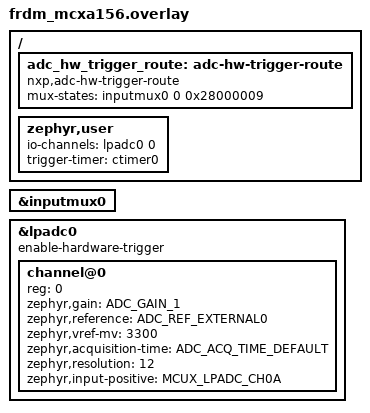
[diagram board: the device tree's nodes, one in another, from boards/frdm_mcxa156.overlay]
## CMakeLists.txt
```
# SPDX-FileCopyrightText: Copyright 2026 NXP
# SPDX-License-Identifier: Apache-2.0

cmake_minimum_required(VERSION 3.20.0)

# Make the sample-local DTS binding visible to the Zephyr DTS toolchain.
# DTS_ROOT must be set before find_package(Zephyr).
list(APPEND DTS_ROOT ${CMAKE_CURRENT_SOURCE_DIR})

find_package(Zephyr REQUIRED HINTS $ENV{ZEPHYR_BASE})
project(trgmux_adc)

target_sources(app PRIVATE src/main.c)
```

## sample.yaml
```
sample:
  name: ADC Hardware Trigger via Signal Router
  description: >
    Demonstrates routing a periodic timer output to an ADC trigger input via a
    signal-routing peripheral (TRGMUX, INPUTMUX, XBAR, …). The C source is
    platform-agnostic; all per-board wiring lives in the board overlay.

tests:
  sample.drivers.mux.trgmux_adc:
    platform_allow:
      - frdm_mcxe247
      - frdm_mcxa156
    tags:
      - adc
      - mux
      - counter
      - drivers
    harness: console
    harness_config:
      type: one_line
      regex:
        - "ADC reading"
```

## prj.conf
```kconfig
CONFIG_ADC=y
CONFIG_COUNTER=y
CONFIG_MUX=y
CONFIG_LOG=y
```

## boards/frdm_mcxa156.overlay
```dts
/*
 * SPDX-FileCopyrightText: Copyright 2026 NXP
 * SPDX-License-Identifier: Apache-2.0
 *
 * frdm_mcxa156: Route CTimer0 match-0 output to LPADC0 trigger0 via INPUTMUX.
 *
 * CTimer0 and LPADC0 are already enabled in frdm_mcxa156.dts; INPUTMUX is
 * disabled by default in the SoC dtsi and is enabled here.
 *
 * INPUTMUX cell values (MCXA156 fsl_inputmux_connections.h):
 *   index      0          = kINPUTMUX_INDEX_ADC0_TRIGSEL0 (ADC0 trigger-select 0)
 *   connection 0x28000009 = kINPUTMUX_Ctimer0M0ToAdc0Trigger
 *                         = 9U + (ADC0_TRIG0_REG << PMUX_SHIFT)
 *                         = 9  + (0x280 << 20)
 *
 * LPADC0 channel 0 side-A = ADC0_A0 on P2_0 (Arduino A0 / J4 pin 8).
 * Connect a 0–3.3 V signal to that pin to observe a non-zero reading.
 */

#include <zephyr/dt-bindings/adc/adc.h>
#include <zephyr/dt-bindings/adc/mcux-lpadc.h>

&inputmux0 {
	status = "okay";
};

&lpadc0 {
	enable-hardware-trigger;
	#address-cells = <1>;
	#size-cells = <0>;

	/*
	 * ADC0_A0 on P2_0 — already covered by pinmux_lpadc0 in board dts.
	 * Connect a 0–3.3 V signal here to verify the reading.
	 */
	channel@0 {
		reg = <0>;
		zephyr,gain = "ADC_GAIN_1";
		zephyr,reference = "ADC_REF_EXTERNAL0";
		zephyr,vref-mv = <3300>;
		zephyr,acquisition-time = <ADC_ACQ_TIME_DEFAULT>;
		zephyr,resolution = <12>;
		zephyr,input-positive = <MCUX_LPADC_CH0A>;
	};
};

/ {
	/*
	 * Signal routing: CTimer0 match-0 output -> LPADC0 trigger-select 0.
	 * mux-states cell order: <controller index connection>.
	 */
	adc_hw_trigger_route: adc-hw-trigger-route {
		compatible = "nxp,adc-hw-trigger-route";
		mux-states = <&inputmux0 0 0x28000009>;
	};

	zephyr,user {
		io-channels = <&lpadc0 0>;
		trigger-timer = <&ctimer0>;
	};
};
```

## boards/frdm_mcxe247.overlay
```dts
/*
 * SPDX-FileCopyrightText: Copyright 2026 NXP
 * SPDX-License-Identifier: Apache-2.0
 *
 * frdm_mcxe247: Route LPIT ch0 periodic trigger to ADC0 via TRGMUX.
 *
 * LPIT0 and ADC0 are already enabled in frdm_mcxe247.dts; TRGMUX is
 * disabled by default in the SoC dtsi and is enabled here.
 *
 * TRGMUX cell values (MCXE247 periph0/PERI_TRGMUX.h):
 *   device 3  = kTRGMUX_Adc0          (ADC0 trigger input)
 *   input  0  = kTRGMUX_TriggerInput0
 *   source 17 = kTRGMUX_SourceLpitCh0 (LPIT channel 0 output)
 *
 * ADC0 channel 1 = ADC0_SE1 on PTA1 (Arduino A1 / J4 pin 10 on the board).
 * Connect a 0–3.3 V signal to that pin to observe a non-zero reading.
 */

&trgmux {
	status = "okay";
};

&adc0 {
	enable-hardware-trigger;
	#address-cells = <1>;
	#size-cells = <0>;

	/*
	 * ADC0_SE1 on PTA1 — already covered by pinmux_adc0 in board dts.
	 * Connect a 0–3.3 V signal here to verify the reading.
	 */
	channel@1 {
		reg = <1>;
		zephyr,gain = "ADC_GAIN_1";
		zephyr,reference = "ADC_REF_INTERNAL";
		zephyr,vref-mv = <3300>;
		zephyr,acquisition-time = <ADC_ACQ_TIME_DEFAULT>;
		zephyr,resolution = <12>;
	};
};

/ {
	/*
	 * Signal routing: LPIT ch0 output (source 17) -> ADC0 trigger input 0
	 * (device 3).  mux-states cell order: <controller device input source>.
	 */
	adc_hw_trigger_route: adc-hw-trigger-route {
		compatible = "nxp,adc-hw-trigger-route";
		mux-states = <&trgmux 3 0 17>;
	};

	zephyr,user {
		io-channels = <&adc0 1>;
		trigger-timer = <&lpit0_channel0>;
	};
};
```

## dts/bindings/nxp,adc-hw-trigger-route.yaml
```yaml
# SPDX-FileCopyrightText: Copyright 2026 NXP
# SPDX-License-Identifier: Apache-2.0

description: |
  ADC hardware trigger route node for the trgmux_adc sample.
  Holds a mux-states specifier that routes a timer trigger output to
  an ADC trigger input via a signal-routing peripheral.

compatible: "nxp,adc-hw-trigger-route"

include: [base.yaml, mux-consumer.yaml]
```

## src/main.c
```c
/*
 * SPDX-FileCopyrightText: Copyright 2026 NXP
 * SPDX-License-Identifier: Apache-2.0
 *
 * ADC hardware trigger via signal router (TRGMUX / INPUTMUX / XBAR).
 *
 * Platform-agnostic flow:
 *   1. Apply the DT-defined signal route (mux-states) so the timer output
 *      is connected to the ADC trigger input.
 *   2. Configure the ADC channel.
 *   3. Register a counter top callback and start the periodic timer.
 *   4. The callback fires in ISR context on every timer overflow; it submits
 *      a k_work item to the system work queue.
 *   5. The work handler calls adc_read_dt() in thread context (required
 *      because adc_read_dt blocks on a semaphore), then prints the result.
 *   6. main() returns after setup; all sampling is driven by the hardware
 *      timer with no software polling loop.
 *
 * All per-platform wiring (which mux controller, which ADC, which timer,
 * and the concrete routing cell values) lives in the board overlay.
 */

#include <zephyr/device.h>
#include <zephyr/devicetree.h>
#include <zephyr/drivers/adc.h>
#include <zephyr/drivers/counter.h>
#include <zephyr/drivers/mux.h>
#include <zephyr/kernel.h>
#include <zephyr/sys/printk.h>

/* ---- Devicetree nodes --------------------------------------------------- */

#define ROUTE_NODE DT_NODELABEL(adc_hw_trigger_route)
#define USER_NODE  DT_PATH(zephyr_user)

BUILD_ASSERT(DT_NODE_EXISTS(ROUTE_NODE),
	     "board overlay must define an 'adc-hw-trigger-route' node");
BUILD_ASSERT(DT_NODE_HAS_PROP(USER_NODE, io_channels),
	     "board overlay must add 'io-channels' to /zephyr,user");
BUILD_ASSERT(DT_NODE_HAS_PROP(USER_NODE, trigger_timer),
	     "board overlay must add 'trigger-timer' to /zephyr,user");

/* DT-defined signal route (mux-states entry 0). */
MUX_STATE_DT_SPEC_DEFINE(ROUTE_NODE);

/* ADC channel from /zephyr,user io-channels[0]. */
static const struct adc_dt_spec adc_chan = ADC_DT_SPEC_GET(USER_NODE);

/* Timer that generates the periodic hardware trigger. */
static const struct device *const timer_dev =
	DEVICE_DT_GET(DT_PHANDLE(USER_NODE, trigger_timer));

/* MUX controller resolved from the route node. */
static const struct device *const mux_dev = MUX_STATE_DT_DEV_GET(ROUTE_NODE);

/* ---- Configuration ------------------------------------------------------ */

/* ADC sampling rate in Hz. The timer top value is derived from the counter
 * frequency at runtime so no board-specific Kconfig is needed.
 */
#define SAMPLE_RATE_HZ 100U

/* ---- ADC sampling work -------------------------------------------------- */

static uint32_t adc_buf;
static struct adc_sequence seq = {
	.buffer      = &adc_buf,
	.buffer_size = sizeof(adc_buf),
};
static uint32_t sample_count;

/*
 * Work item executed in thread context on every timer tick.
 *
 * adc_read_dt() arms the ADC channel and blocks until the conversion is
 * complete.  In hardware-trigger mode the ADC waits for the external pulse
 * (already routed by the mux) rather than issuing a software trigger, so
 * the actual sampling instant is controlled by the hardware timer, not by
 * when this work item happens to be scheduled.
 */
static void adc_sample_work_handler(struct k_work *work)
{
	ARG_UNUSED(work);

	int ret = adc_read_dt(&adc_chan, &seq);

	if (ret < 0) {
		printk("ADC read error: %d\n", ret);
		return;
	}

	int32_t val_mv = (int32_t)adc_buf;

	ret = adc_raw_to_millivolts_dt(&adc_chan, &val_mv);
	if (ret < 0) {
		printk("ADC reading[%u]: raw=0x%04x "
		       "(conversion to mV not supported)\n",
		       sample_count, adc_buf);
	} else {
		printk("ADC reading[%u]: %d mV\n", sample_count, val_mv);
	}

	sample_count++;
}

static K_WORK_DEFINE(adc_sample_work, adc_sample_work_handler);

/*
 * Counter top callback — runs in ISR context on every timer overflow.
 *
 * Only submits the work item; must not call adc_read_dt() directly because
 * that function blocks on a semaphore.
 */
static void timer_top_cb(const struct device *dev, void *user_data)
{
	ARG_UNUSED(dev);
	ARG_UNUSED(user_data);

	k_work_submit(&adc_sample_work);
}

/* ---- main --------------------------------------------------------------- */

int main(void)
{
	int ret;

	/* 1. Verify all devices are ready. */
	if (!device_is_ready(mux_dev)) {
		printk("MUX controller not ready\n");
		return -ENODEV;
	}
	if (!device_is_ready(timer_dev)) {
		printk("Timer device not ready\n");
		return -ENODEV;
	}
	if (!adc_is_ready_dt(&adc_chan)) {
		printk("ADC controller not ready\n");
		return -ENODEV;
	}

	/* 2. Apply the DT-defined routing: timer output -> ADC trigger input. */
	ret = mux_state_apply(mux_dev, MUX_STATE_DT_GET(ROUTE_NODE));
	if (ret < 0) {
		printk("Failed to apply mux route: %d\n", ret);
		return ret;
	}
	printk("Signal route applied\n");

	/* 3. Configure the ADC channel and initialise the sequence once. */
	ret = adc_channel_setup_dt(&adc_chan);
	if (ret < 0) {
		printk("Failed to set up ADC channel: %d\n", ret);
		return ret;
	}

	ret = adc_sequence_init_dt(&adc_chan, &seq);
	if (ret < 0) {
		printk("Failed to init ADC sequence: %d\n", ret);
		return ret;
	}

	/* 4. Configure the timer: derive the top value from the counter
	 *    frequency so the same source works on any supported board.
	 */
	uint32_t timer_freq = counter_get_frequency(timer_dev);

	if (timer_freq == 0U) {
		printk("Counter frequency unknown\n");
		return -EINVAL;
	}

	struct counter_top_cfg top_cfg = {
		.ticks     = timer_freq / SAMPLE_RATE_HZ,
		.callback  = timer_top_cb,
		.user_data = NULL,
		.flags     = 0,
	};

	ret = counter_set_top_value(timer_dev, &top_cfg);
	if (ret < 0) {
		printk("Failed to set timer period: %d\n", ret);
		return ret;
	}

	/* 5. Start the timer. From this point every overflow fires timer_top_cb
	 *    which submits adc_sample_work. main() is no longer needed.
	 */
	ret = counter_start(timer_dev);
	if (ret < 0) {
		printk("Failed to start timer: %d\n", ret);
		return ret;
	}

	printk("Timer started at %u Hz (top=%u ticks) — sampling driven by hardware\n",
	       SAMPLE_RATE_HZ, top_cfg.ticks);

	/* main() exits; the system work queue services adc_sample_work
	 * indefinitely. The Zephyr idle thread runs when no work is pending,
	 * allowing the SoC to enter sleep states between samples.
	 */
	return 0;
}
```
